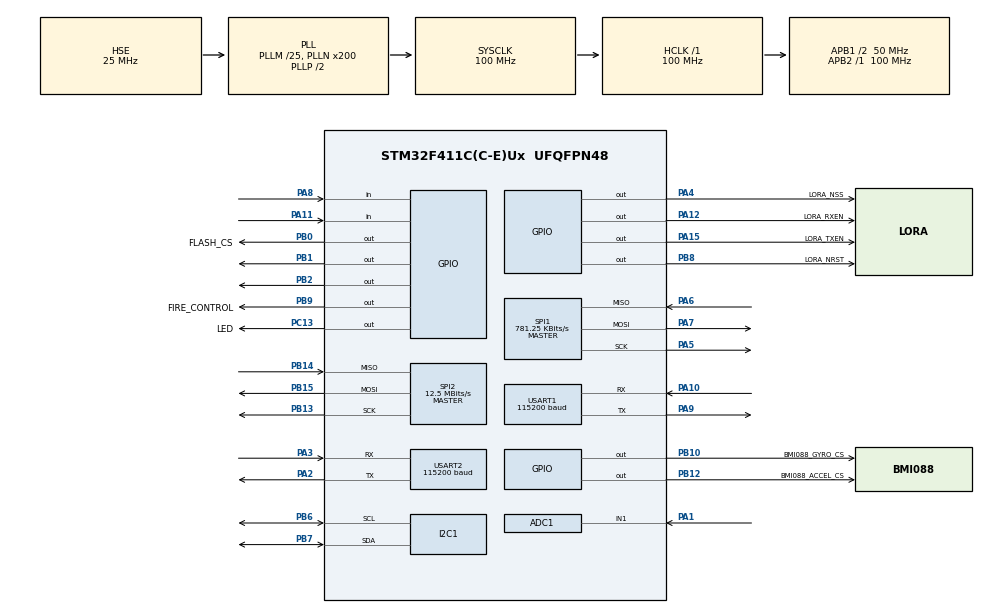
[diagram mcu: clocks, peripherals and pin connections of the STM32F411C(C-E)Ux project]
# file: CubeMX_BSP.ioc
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ADC1.Channel-0\#ChannelRegularConversion=ADC_CHANNEL_1
ADC1.ContinuousConvMode=DISABLE
ADC1.NbrOfConversionFlag=1
ADC1.Rank-0\#ChannelRegularConversion=1
ADC1.SamplingTime-0\#ChannelRegularConversion=ADC_SAMPLETIME_144CYCLES
ADC1.master=1
Dma.Request0=USART1_RX
Dma.Request1=USART1_TX
Dma.Request2=USART2_RX
Dma.Request3=USART2_TX
Dma.USART1_RX.0.Direction=DMA_PERIPH_TO_MEMORY
Dma.USART1_RX.0.FIFOMode=DMA_FIFOMODE_DISABLE
Dma.USART1_RX.0.Instance=DMA2_Stream2
Dma.USART1_RX.0.MemDataAlignment=DMA_MDATAALIGN_BYTE
Dma.USART1_RX.0.MemInc=DMA_MINC_ENABLE
Dma.USART1_RX.0.Mode=DMA_NORMAL
Dma.USART1_RX.0.PeriphDataAlignment=DMA_PDATAALIGN_BYTE
Dma.USART1_RX.0.PeriphInc=DMA_PINC_DISABLE
Dma.USART1_RX.0.Priority=DMA_PRIORITY_LOW
Dma.USART1_TX.1.Direction=DMA_MEMORY_TO_PERIPH
Dma.USART1_TX.1.FIFOMode=DMA_FIFOMODE_DISABLE
Dma.USART1_TX.1.Instance=DMA2_Stream7
Dma.USART1_TX.1.MemDataAlignment=DMA_MDATAALIGN_BYTE
Dma.USART1_TX.1.MemInc=DMA_MINC_ENABLE
Dma.USART1_TX.1.Mode=DMA_NORMAL
Dma.USART1_TX.1.PeriphDataAlignment=DMA_PDATAALIGN_BYTE
Dma.USART1_TX.1.PeriphInc=DMA_PINC_DISABLE
Dma.USART1_TX.1.Priority=DMA_PRIORITY_LOW
Dma.USART2_RX.2.Direction=DMA_PERIPH_TO_MEMORY
Dma.USART2_RX.2.FIFOMode=DMA_FIFOMODE_DISABLE
Dma.USART2_RX.2.Instance=DMA1_Stream5
Dma.USART2_RX.2.MemDataAlignment=DMA_MDATAALIGN_BYTE
Dma.USART2_RX.2.MemInc=DMA_MINC_ENABLE
Dma.USART2_RX.2.Mode=DMA_NORMAL
Dma.USART2_RX.2.PeriphDataAlignment=DMA_PDATAALIGN_BYTE
Dma.USART2_RX.2.PeriphInc=DMA_PINC_DISABLE
Dma.USART2_RX.2.Priority=DMA_PRIORITY_LOW
Dma.USART2_TX.3.Direction=DMA_MEMORY_TO_PERIPH
Dma.USART2_TX.3.FIFOMode=DMA_FIFOMODE_DISABLE
Dma.USART2_TX.3.Instance=DMA1_Stream6
Dma.USART2_TX.3.MemDataAlignment=DMA_MDATAALIGN_BYTE
Dma.USART2_TX.3.MemInc=DMA_MINC_ENABLE
Dma.USART2_TX.3.Mode=DMA_NORMAL
Dma.USART2_TX.3.PeriphDataAlignment=DMA_PDATAALIGN_BYTE
Dma.USART2_TX.3.PeriphInc=DMA_PINC_DISABLE
Dma.USART2_TX.3.Priority=DMA_PRIORITY_LOW
FREERTOS.Tasks01=Rocket,32,3072,rocket_task,As weak,NULL,Static,RocketBuffer,RocketControlBlock;GNSS,32,512,GNSS_task,As weak,NULL,Static,GNSSBuffer,GNSSControlBlock;IMU,40,1024,imu_task,As weak,NULL,Static,IMUBuffer,IMUControlBlock;LOG,24,512,log_task,As weak,NULL,Static,LOGBuffer,LOGControlBlock;LORA,24,512,lora_task,As weak,NULL,Static,LORABuffer,LORAControlBlock
Mcu.Family=STM32F4
Mcu.Name=STM32F411C(C-E)Ux
Mcu.Package=UFQFPN48
NVIC.DMA1_Stream5_IRQn=true\:5\:0\:false\:false\:true\:true\:false\:true\:true
NVIC.DMA1_Stream6_IRQn=true\:5\:0\:false\:false\:true\:true\:false\:true\:true
NVIC.DMA2_Stream2_IRQn=true\:5\:0\:false\:false\:true\:true\:false\:true\:true
NVIC.DMA2_Stream7_IRQn=true\:5\:0\:false\:false\:true\:true\:false\:true\:true
NVIC.PriorityGroup=NVIC_PRIORITYGROUP_4
NVIC.SPI1_IRQn=true\:5\:0\:false\:false\:true\:true\:true\:true\:true
NVIC.SPI2_IRQn=true\:5\:0\:false\:false\:true\:true\:true\:true\:true
NVIC.TIM1_UP_TIM10_IRQn=true\:15\:0\:false\:false\:true\:false\:false\:true\:true
NVIC.TimeBase=TIM1_UP_TIM10_IRQn
NVIC.TimeBaseIP=TIM1
NVIC.USART1_IRQn=true\:5\:0\:false\:false\:true\:true\:true\:true\:true
NVIC.USART2_IRQn=true\:5\:0\:false\:false\:true\:true\:true\:true\:true
PA1.Signal=ADCx_IN1
PA10.Mode=Asynchronous
PA10.Signal=USART1_RX
PA11.Signal=GPIO_Input
PA12.GPIO_Label=LORA_RXEN
PA12.Signal=GPIO_Output
PA13.Mode=Serial_Wire
PA13.Signal=SYS_JTMS-SWDIO
PA14.Mode=Serial_Wire
PA14.Signal=SYS_JTCK-SWCLK
PA15.GPIO_Label=LORA_TXEN
PA15.Signal=GPIO_Output
PA2.Mode=Asynchronous
PA2.Signal=USART2_TX
PA3.Mode=Asynchronous
PA3.Signal=USART2_RX
PA4.GPIO_Label=LORA_NSS
PA4.GPIO_Speed=GPIO_SPEED_FREQ_HIGH
PA4.PinState=GPIO_PIN_SET
PA4.Signal=GPIO_Output
PA5.Mode=Full_Duplex_Master
PA5.Signal=SPI1_SCK
PA6.Mode=Full_Duplex_Master
PA6.Signal=SPI1_MISO
PA7.Mode=Full_Duplex_Master
PA7.Signal=SPI1_MOSI
PA8.Signal=GPIO_Input
PA9.Mode=Asynchronous
PA9.Signal=USART1_TX
PB0.GPIO_Label=FLASH_CS
PB0.GPIO_Speed=GPIO_SPEED_FREQ_HIGH
PB0.PinState=GPIO_PIN_SET
PB0.Signal=GPIO_Output
PB1.GPIO_Speed=GPIO_SPEED_FREQ_HIGH
PB1.PinState=GPIO_PIN_SET
PB1.Signal=GPIO_Output
PB10.GPIO_Label=BMI088_GYRO_CS
PB10.Signal=GPIO_Output
PB12.GPIO_Label=BMI088_ACCEL_CS
PB12.Signal=GPIO_Output
PB13.Mode=Full_Duplex_Master
PB13.Signal=SPI2_SCK
PB14.Mode=Full_Duplex_Master
PB14.Signal=SPI2_MISO
PB15.Mode=Full_Duplex_Master
PB15.Signal=SPI2_MOSI
PB2.Signal=GPIO_Output
PB6.Mode=I2C
PB6.Signal=I2C1_SCL
PB7.Mode=I2C
PB7.Signal=I2C1_SDA
PB8.GPIO_Label=LORA_NRST
PB8.PinState=GPIO_PIN_SET
PB8.Signal=GPIO_Output
PB9.GPIO_Label=FIRE_CONTROL
PB9.PinState=GPIO_PIN_RESET
PB9.Signal=GPIO_Output
PC13-ANTI_TAMP.GPIO_Label=LED
PC13-ANTI_TAMP.Signal=GPIO_Output
PC14-OSC32_IN.Mode=LSE-External-Oscillator
PC14-OSC32_IN.Signal=RCC_OSC32_IN
PC15-OSC32_OUT.Mode=LSE-External-Oscillator
PC15-OSC32_OUT.Signal=RCC_OSC32_OUT
PH0\ -\ OSC_IN.Mode=HSE-External-Oscillator
PH0\ -\ OSC_IN.Signal=RCC_OSC_IN
PH1\ -\ OSC_OUT.Mode=HSE-External-Oscillator
PH1\ -\ OSC_OUT.Signal=RCC_OSC_OUT
ProjectManager.HeapSize=0x200
ProjectManager.StackSize=0x400
ProjectManager.TargetToolchain=CMake
RCC.48MHZClocksFreq_Value=50000000
RCC.AHBFreq_Value=100000000
RCC.APB1CLKDivider=RCC_HCLK_DIV2
RCC.APB1Freq_Value=50000000
RCC.APB1TimFreq_Value=100000000
RCC.APB2Freq_Value=100000000
RCC.APB2TimFreq_Value=100000000
RCC.CortexFreq_Value=100000000
RCC.HCLKFreq_Value=100000000
RCC.HSE_VALUE=25000000
RCC.HSI_VALUE=16000000
RCC.PLLM=25
RCC.PLLN=200
RCC.PLLSourceVirtual=RCC_PLLSOURCE_HSE
RCC.SYSCLKFreq_VALUE=100000000
RCC.SYSCLKSource=RCC_SYSCLKSOURCE_PLLCLK
RCC.VCOOutputFreq_Value=200000000
SH.ADCx_IN1.0=ADC1_IN1,IN1
SPI1.BaudRatePrescaler=SPI_BAUDRATEPRESCALER_128
SPI1.CLKPhase=SPI_PHASE_2EDGE
SPI1.CLKPolarity=SPI_POLARITY_HIGH
SPI1.CalculateBaudRate=781.25 KBits/s
SPI1.Direction=SPI_DIRECTION_2LINES
SPI1.Mode=SPI_MODE_MASTER
SPI1.VirtualType=VM_MASTER
SPI2.BaudRatePrescaler=SPI_BAUDRATEPRESCALER_4
SPI2.CLKPhase=SPI_PHASE_1EDGE
SPI2.CLKPolarity=SPI_POLARITY_LOW
SPI2.CalculateBaudRate=12.5 MBits/s
SPI2.Direction=SPI_DIRECTION_2LINES
SPI2.Mode=SPI_MODE_MASTER
SPI2.VirtualType=VM_MASTER
TIM2.Prescaler=99
USART1.BaudRate=115200
USART1.VirtualMode=VM_ASYNC
USART2.BaudRate=115200
USART2.VirtualMode=VM_ASYNC
VP_FREERTOS_VS_CMSIS_V2.Mode=CMSIS_V2
VP_SYS_VS_tim1.Mode=TIM1
VP_TIM2_VS_ClockSourceINT.Mode=Internal
board=custom

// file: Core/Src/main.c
/* USER CODE BEGIN Header */
/**
  ******************************************************************************
  * @file           : main.c
  * @brief          : Main program body
  ******************************************************************************
  * @attention
  *
  * Copyright (c) 2026 STMicroelectronics.
  * All rights reserved.
  *
  * This software is licensed under terms that can be found in the LICENSE file
  * in the root directory of this software component.
  * If no LICENSE file comes with this software, it is provided AS-IS.
  *
  ******************************************************************************
  */
/* USER CODE END Header */
#include "main.h"
#include "cmsis_os.h"
#include "adc.h"
#include "dma.h"
#include "i2c.h"
#include "spi.h"
#include "tim.h"
#include "usart.h"
#include "gpio.h"

void SystemClock_Config(void);
void MX_FREERTOS_Init(void);

int main(void)
{

  /* MCU Configuration--------------------------------------------------------*/

  /* Reset of all peripherals, Initializes the Flash interface and the Systick. */
  HAL_Init();

  /* Configure the system clock */
  SystemClock_Config();

  /* Initialize all configured peripherals */
  MX_GPIO_Init();
  MX_DMA_Init();
  MX_I2C1_Init();
  MX_SPI1_Init();
  MX_USART1_UART_Init();
  MX_TIM2_Init();
  MX_ADC1_Init();
  MX_USART2_UART_Init();
  MX_SPI2_Init();
  /* USER CODE BEGIN 2 */
  HAL_TIM_Base_Start(&htim2);
  /* USER CODE END 2 */

  /* Init scheduler */
  osKernelInitialize();  /* Call init function for freertos objects (in cmsis_os2.c) */
  MX_FREERTOS_Init();

  /* Start scheduler */
  osKernelStart();

  /* We should never get here as control is now taken by the scheduler */

  /* Infinite loop */
  while (1)
  {

  }
}

void SystemClock_Config(void)
{
  RCC_OscInitTypeDef RCC_OscInitStruct = {0};
  RCC_ClkInitTypeDef RCC_ClkInitStruct = {0};

  /** Configure the main internal regulator output voltage
  */
  __HAL_RCC_PWR_CLK_ENABLE();
  __HAL_PWR_VOLTAGESCALING_CONFIG(PWR_REGULATOR_VOLTAGE_SCALE1);

  /** Initializes the RCC Oscillators according to the specified parameters
  * in the RCC_OscInitTypeDef structure.
  */
  RCC_OscInitStruct.OscillatorType = RCC_OSCILLATORTYPE_HSE;
  RCC_OscInitStruct.HSEState = RCC_HSE_ON;
  RCC_OscInitStruct.PLL.PLLState = RCC_PLL_ON;
  RCC_OscInitStruct.PLL.PLLSource = RCC_PLLSOURCE_HSE;
  RCC_OscInitStruct.PLL.PLLM = 25;
  RCC_OscInitStruct.PLL.PLLN = 200;
  RCC_OscInitStruct.PLL.PLLP = RCC_PLLP_DIV2;
  RCC_OscInitStruct.PLL.PLLQ = 4;
  if (HAL_RCC_OscConfig(&RCC_OscInitStruct) != HAL_OK)
  {
    Error_Handler();
  }

  /** Initializes the CPU, AHB and APB buses clocks
  */
  RCC_ClkInitStruct.ClockType = RCC_CLOCKTYPE_HCLK|RCC_CLOCKTYPE_SYSCLK
                              |RCC_CLOCKTYPE_PCLK1|RCC_CLOCKTYPE_PCLK2;
  RCC_ClkInitStruct.SYSCLKSource = RCC_SYSCLKSOURCE_PLLCLK;
  RCC_ClkInitStruct.AHBCLKDivider = RCC_SYSCLK_DIV1;
  RCC_ClkInitStruct.APB1CLKDivider = RCC_HCLK_DIV2;
  RCC_ClkInitStruct.APB2CLKDivider = RCC_HCLK_DIV1;

  if (HAL_RCC_ClockConfig(&RCC_ClkInitStruct, FLASH_LATENCY_3) != HAL_OK)
  {
    Error_Handler();
  }
}

void HAL_TIM_PeriodElapsedCallback(TIM_HandleTypeDef *htim)
{
  if (htim->Instance == TIM1)
  {
    HAL_IncTick();
  }
}

void Error_Handler(void)
{
  __disable_irq();
  while (1)
  {
  }
}

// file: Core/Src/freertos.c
/* USER CODE BEGIN Header */
/**
  ******************************************************************************
  * File Name          : freertos.c
  * Description        : Code for freertos applications
  ******************************************************************************
  * @attention
  *
  * Copyright (c) 2026 STMicroelectronics.
  * All rights reserved.
  *
  * This software is licensed under terms that can be found in the LICENSE file
  * in the root directory of this software component.
  * If no LICENSE file comes with this software, it is provided AS-IS.
  *
  ******************************************************************************
  */
/* USER CODE END Header */

#include "FreeRTOS.h"
#include "task.h"
#include "main.h"
#include "cmsis_os.h"

/* USER CODE BEGIN Includes */
#include "app_systemview.h"
/* USER CODE END Includes */

typedef StaticTask_t osStaticThreadDef_t;

/* Definitions for Rocket */
osThreadId_t RocketHandle;
uint32_t RocketBuffer[ 3072 ];
osStaticThreadDef_t RocketControlBlock;
const osThreadAttr_t Rocket_attributes = {
  .name = "Rocket",
  .cb_mem = &RocketControlBlock,
  .cb_size = sizeof(RocketControlBlock),
  .stack_mem = &RocketBuffer[0],
  .stack_size = sizeof(RocketBuffer),
  .priority = (osPriority_t) osPriorityAboveNormal,
};
/* Definitions for GNSS */
osThreadId_t GNSSHandle;
uint32_t GNSSBuffer[ 512 ];
osStaticThreadDef_t GNSSControlBlock;
const osThreadAttr_t GNSS_attributes = {
  .name = "GNSS",
  .cb_mem = &GNSSControlBlock,
  .cb_size = sizeof(GNSSControlBlock),
  .stack_mem = &GNSSBuffer[0],
  .stack_size = sizeof(GNSSBuffer),
  .priority = (osPriority_t) osPriorityAboveNormal,
};
/* Definitions for IMU */
osThreadId_t IMUHandle;
uint32_t IMUBuffer[ 1024 ];
osStaticThreadDef_t IMUControlBlock;
const osThreadAttr_t IMU_attributes = {
  .name = "IMU",
  .cb_mem = &IMUControlBlock,
  .cb_size = sizeof(IMUControlBlock),
  .stack_mem = &IMUBuffer[0],
  .stack_size = sizeof(IMUBuffer),
  .priority = (osPriority_t) osPriorityHigh,
};
/* Definitions for LOG */
osThreadId_t LOGHandle;
uint32_t LOGBuffer[ 512 ];
osStaticThreadDef_t LOGControlBlock;
const osThreadAttr_t LOG_attributes = {
  .name = "LOG",
  .cb_mem = &LOGControlBlock,
  .cb_size = sizeof(LOGControlBlock),
  .stack_mem = &LOGBuffer[0],
  .stack_size = sizeof(LOGBuffer),
  .priority = (osPriority_t) osPriorityNormal,
};
/* Definitions for LORA */
osThreadId_t LORAHandle;
uint32_t LORABuffer[ 512 ];
osStaticThreadDef_t LORAControlBlock;
const osThreadAttr_t LORA_attributes = {
  .name = "LORA",
  .cb_mem = &LORAControlBlock,
  .cb_size = sizeof(LORAControlBlock),
  .stack_mem = &LORABuffer[0],
  .stack_size = sizeof(LORABuffer),
  .priority = (osPriority_t) osPriorityNormal,
};

void rocket_task(void *argument);
void GNSS_task(void *argument);
void imu_task(void *argument);
void log_task(void *argument);
void lora_task(void *argument);

void MX_FREERTOS_Init(void); /* (MISRA C 2004 rule 8.1) */

void MX_FREERTOS_Init(void) {
  /* USER CODE BEGIN Init */
  AppSystemView_Init();
  /* USER CODE END Init */

  /* Create the thread(s) */
  /* creation of Rocket */
  RocketHandle = osThreadNew(rocket_task, NULL, &Rocket_attributes);

  /* creation of GNSS */
  GNSSHandle = osThreadNew(GNSS_task, NULL, &GNSS_attributes);

  /* creation of IMU */
  IMUHandle = osThreadNew(imu_task, NULL, &IMU_attributes);

  /* creation of LOG */
  LOGHandle = osThreadNew(log_task, NULL, &LOG_attributes);

  /* creation of LORA */
  LORAHandle = osThreadNew(lora_task, NULL, &LORA_attributes);

}

__weak void rocket_task(void *argument)
{
  for(;;)
  {
    osDelay(1);
  }
}

__weak void GNSS_task(void *argument)
{
  for(;;)
  {
    osDelay(1);
  }
}

__weak void imu_task(void *argument)
{
  for(;;)
  {
    osDelay(1);
  }
}

__weak void log_task(void *argument)
{
  for(;;)
  {
    osDelay(1);
  }
}

__weak void lora_task(void *argument)
{
  for(;;)
  {
    osDelay(1);
  }
}
